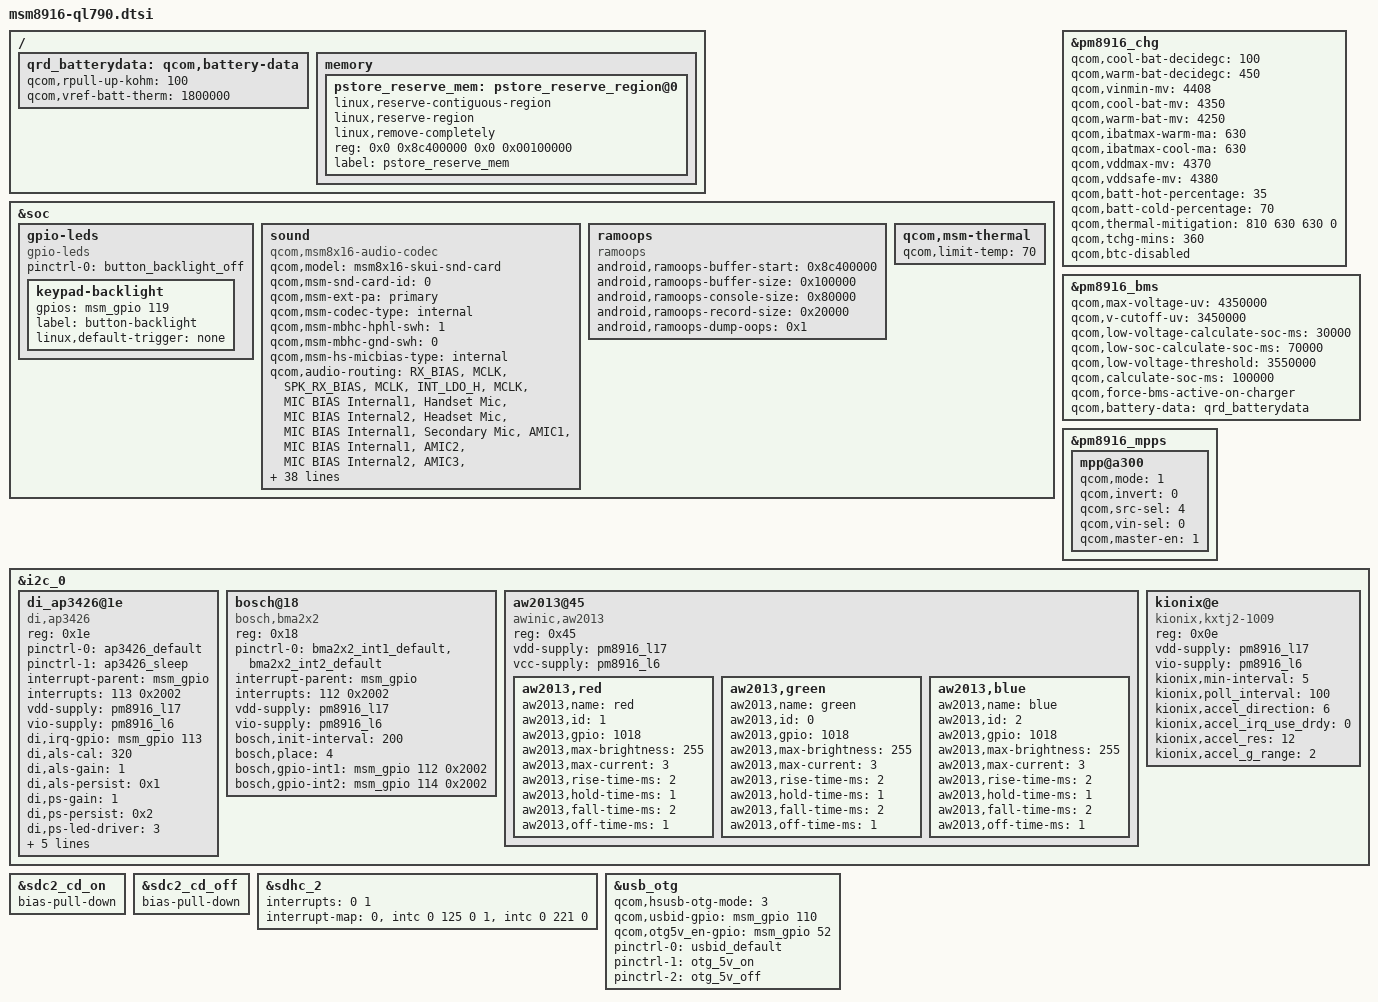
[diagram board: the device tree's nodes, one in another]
/* Copyright (c) 2014, The Linux Foundation. All rights reserved.
 *
 * This program is free software; you can redistribute it and/or modify
 * it under the terms of the GNU General Public License version 2 and
 * only version 2 as published by the Free Software Foundation.
 *
 * This program is distributed in the hope that it will be useful,
 * but WITHOUT ANY WARRANTY; without even the implied warranty of
 * MERCHANTABILITY or FITNESS FOR A PARTICULAR PURPOSE.  See the
 * GNU General Public License for more details.
 */

#include "msm8916-ql790-misc.dtsi"
#include "msm8916-ql790-camera.dtsi"
#include "msm8916-ql790-lcd_panel-settings.dtsi"
#include "msm8916-ql790-pm8916.dtsi"
#include "msm8916-ql790-tp.dtsi"

&soc {
	gpio-leds {
		compatible = "gpio-leds";
		status = "okay";
		pinctrl-names = "default";
		pinctrl-0 = <&button_backlight_off>;

		keypad-backlight {
			gpios = <&msm_gpio 119 0>;
			label = "button-backlight";
			linux,default-trigger = "none";
		};
	};

	sound {
		compatible = "qcom,msm8x16-audio-codec";
		qcom,model = "msm8x16-skui-snd-card";
		qcom,msm-snd-card-id = <0>;
		qcom,msm-ext-pa = "primary";
		qcom,msm-codec-type = "internal";
		qcom,msm-mbhc-hphl-swh = <1>;
		qcom,msm-mbhc-gnd-swh = <0>;
		qcom,msm-hs-micbias-type = "internal";
		qcom,audio-routing =
			"RX_BIAS", "MCLK",
			"SPK_RX_BIAS", "MCLK",
			"INT_LDO_H", "MCLK",
			"MIC BIAS Internal1", "Handset Mic",
			"MIC BIAS Internal2", "Headset Mic",
			"MIC BIAS Internal1", "Secondary Mic",
			"AMIC1", "MIC BIAS Internal1",
			"AMIC2", "MIC BIAS Internal2",
			"AMIC3", "MIC BIAS Internal1";
		pinctrl-names = "cdc_lines_act",
				"cdc_lines_sus";
		pinctrl-0 = <&cdc_pdm_lines_act>;
		pinctrl-1 = <&cdc_pdm_lines_sus>;
		qcom,ext-spk-amp-gpio = <&msm_gpio 112 0>;
		asoc-platform = <&pcm0>, <&pcm1>, <&voip>, <&voice>,
				<&loopback>, <&compress>, <&hostless>,
				<&afe>, <&lsm>, <&routing>, <&lpa>;
		asoc-platform-names = "msm-pcm-dsp.0", "msm-pcm-dsp.1",
				"msm-voip-dsp", "msm-pcm-voice", "msm-pcm-loopback",
				"msm-compress-dsp", "msm-pcm-hostless", "msm-pcm-afe",
				"msm-lsm-client", "msm-pcm-routing", "msm-pcm-lpa";
		asoc-cpu = <&dai_pri_auxpcm>, <&dai_hdmi>,
				<&dai_mi2s0>, <&dai_mi2s1>, <&dai_mi2s2>, <&dai_mi2s3>,
				<&sb_0_rx>, <&sb_0_tx>, <&sb_1_rx>, <&sb_1_tx>,
				<&sb_3_rx>, <&sb_3_tx>, <&sb_4_rx>, <&sb_4_tx>,
				<&bt_sco_rx>, <&bt_sco_tx>, <&bt_a2dp_rx>,
				<&int_fm_rx>, <&int_fm_tx>,
				<&afe_pcm_rx>, <&afe_pcm_tx>, <&afe_proxy_rx>, <&afe_proxy_tx>,
				<&incall_record_rx>, <&incall_record_tx>, <&incall_music_rx>,
				<&incall_music_2_rx>;
		asoc-cpu-names = "msm-dai-q6-auxpcm.1", "msm-dai-q6-hdmi.8",
				"msm-dai-q6-mi2s.0", "msm-dai-q6-mi2s.1",
				"msm-dai-q6-mi2s.2", "msm-dai-q6-mi2s.3",
				"msm-dai-q6-dev.16384", "msm-dai-q6-dev.16385",
				"msm-dai-q6-dev.16386", "msm-dai-q6-dev.16387",
				"msm-dai-q6-dev.16390", "msm-dai-q6-dev.16391",
				"msm-dai-q6-dev.16392", "msm-dai-q6-dev.16393",
				"msm-dai-q6-dev.12288", "msm-dai-q6-dev.12289",
				"msm-dai-q6-dev.12290", "msm-dai-q6-dev.12292",
				"msm-dai-q6-dev.12293",	"msm-dai-q6-dev.224",
				"msm-dai-q6-dev.225", "msm-dai-q6-dev.241",
				"msm-dai-q6-dev.240", "msm-dai-q6-dev.32771",
				"msm-dai-q6-dev.32772", "msm-dai-q6-dev.32773",
				"msm-dai-q6-dev.32770";
		asoc-codec = <&stub_codec>, <&pm8916_tombak_dig>;
		asoc-codec-names = "msm-stub-codec.1", "tombak_codec";
	};

	ramoops {
		compatible = "ramoops";
		status = "ok";

		android,ramoops-buffer-start = <0x8c400000>;
		android,ramoops-buffer-size = <0x100000>;
		android,ramoops-console-size = <0x80000>;
		android,ramoops-record-size = <0x20000>;
		android,ramoops-dump-oops = <0x1>;
	};

	qcom,msm-thermal {
		qcom,limit-temp = <70>;
	};
};

&pm8916_chg {
	qcom,cool-bat-decidegc = <100>;
	qcom,warm-bat-decidegc = <450>;
	qcom,vinmin-mv = <4408>;
	qcom,cool-bat-mv = <4350>;
	qcom,warm-bat-mv = <4250>;
	qcom,ibatmax-warm-ma = <630>;
	qcom,ibatmax-cool-ma = <630>;
	qcom,vddmax-mv = <4370>;
	qcom,vddsafe-mv = <4380>;
	qcom,batt-hot-percentage = <35>;
	qcom,batt-cold-percentage = <70>;
	qcom,thermal-mitigation = <810 630 630 0>;
	qcom,tchg-mins = <360>;
	status = "okay";
};
&pm8916_bms {
	qcom,max-voltage-uv = <4350000>;
	qcom,v-cutoff-uv = <3450000>;
	qcom,low-voltage-calculate-soc-ms = <30000>;
	qcom,low-soc-calculate-soc-ms = <70000>;
	qcom,low-voltage-threshold = <3550000>;
	qcom,calculate-soc-ms = <100000>;
};

&pm8916_chg {
	status = "ok";
	qcom,btc-disabled;
};

/ {
	qrd_batterydata: qcom,battery-data {
	qcom,rpull-up-kohm = <100>;
	qcom,vref-batt-therm = <1800000>;

		#include "msm8916-ql790-sunwoda-4v35-2000mah.dtsi"
	};
};

&pm8916_bms {
	status = "okay";
	qcom,force-bms-active-on-charger;
	qcom,battery-data = <&qrd_batterydata>;
};

&pm8916_mpps {
	mpp@a300 { /* MPP 4 */
		/* Backlight PWM */
		qcom,mode = <1>;		/* Digital output */
		qcom,invert = <0>;		/* Disable invert */
		qcom,src-sel = <4>;		/* DTEST1 */
		qcom,vin-sel = <0>;		/* VPH_PWR */
		qcom,master-en = <1>;		/* Enable MPP */
	};
};

&i2c_0 { /* BLSP1 QUP2 */
	di_ap3426@1e {
		compatible = "di,ap3426";
		reg = <0x1e>;
		pinctrl-names = "default","sleep";
		pinctrl-0 = <&ap3426_default>;
		pinctrl-1 = <&ap3426_sleep>;
		interrupt-parent = <&msm_gpio>;
		interrupts = <113 0x2002>;
		vdd-supply = <&pm8916_l17>;
		vio-supply = <&pm8916_l6>;
		di,irq-gpio = <&msm_gpio 113 0x2002>;
		di,als-cal = <320>;
		di,als-gain = <1>;
		di,als-persist = <0x1>;
		di,ps-gain = <1>;
		di,ps-persist = <0x2>;
		di,ps-led-driver = <3>;
		di,ps-mean-time = <0x2>;
		di,ps-integrated-time = <0xc>;
		di,wakeup-threshold = <4>;
		di,als-sensitivity = <3000 400 100 1>;
		di,ps-distance-table = <950 500 250 160 105 75>;
	};

	bosch@18 { /* Accelerometer sensor */
		compatible = "bosch,bma2x2";
		reg = <0x18>;
		pinctrl-names = "default";
		pinctrl-0 = <&bma2x2_int1_default &bma2x2_int2_default>;
		interrupt-parent = <&msm_gpio>;
		interrupts = <112 0x2002>;
		vdd-supply = <&pm8916_l17>;
		vio-supply = <&pm8916_l6>;
		bosch,init-interval = <200>;
		bosch,place = <4>;
		bosch,gpio-int1 = <&msm_gpio 112 0x2002>;
		bosch,gpio-int2 = <&msm_gpio 114 0x2002>;
	};

	aw2013@45 {
		compatible = "awinic,aw2013";
		reg = <0x45>;
		vdd-supply = <&pm8916_l17>;
		vcc-supply = <&pm8916_l6>;

		aw2013,red {
			aw2013,name = "red";
			aw2013,id = <1>;
			aw2013,gpio = <1018>;
			aw2013,max-brightness = <255>;
			aw2013,max-current = <3>;
			aw2013,rise-time-ms = <2>;
			aw2013,hold-time-ms = <1>;
			aw2013,fall-time-ms = <2>;
			aw2013,off-time-ms = <1>;
		};

		aw2013,green {
			aw2013,name = "green";
			aw2013,id = <0>;
			aw2013,gpio = <1018>;
			aw2013,max-brightness = <255>;
			aw2013,max-current = <3>;
			aw2013,rise-time-ms = <2>;
			aw2013,hold-time-ms = <1>;
			aw2013,fall-time-ms = <2>;
			aw2013,off-time-ms = <1>;
		};

		aw2013,blue {
			aw2013,name = "blue";
			aw2013,id = <2>;
			aw2013,gpio = <1018>;
			aw2013,max-brightness = <255>;
			aw2013,max-current = <3>;
			aw2013,rise-time-ms = <2>;
			aw2013,hold-time-ms = <1>;
			aw2013,fall-time-ms = <2>;
			aw2013,off-time-ms = <1>;
		};
	};

	kionix@e {
		compatible = "kionix,kxtj2-1009";
		reg = <0x0e>;
		vdd-supply = <&pm8916_l17>;
		vio-supply = <&pm8916_l6>;
		kionix,min-interval = <5>;
		kionix,poll_interval = <100>;
		kionix,accel_direction = <6>;
		kionix,accel_irq_use_drdy = <0>;
		kionix,accel_res = <12>;
		kionix,accel_g_range = <2>;
	};
};

&sdc2_cd_on {
	/delete-property/ bias-pull-up;
	bias-pull-down;
};

&sdc2_cd_off {
	/delete-property/ bias-disable;
	bias-pull-down;
};

&sdhc_2 {
	interrupts = <0 1>;
	interrupt-map = <0 &intc 0 125 0
		1 &intc 0 221 0>;
	interrupt-names = "hc_irq", "pwr_irq";
	/delete-property/ cd-gpios;
};

/ {
	memory {
		pstore_reserve_mem: pstore_reserve_region@0 {
			linux,reserve-contiguous-region;
			linux,reserve-region;
			linux,remove-completely;
			reg = <0x0 0x8c400000 0x0 0x00100000>;
			label = "pstore_reserve_mem";
		};
	};
};

&usb_otg {
	qcom,hsusb-otg-mode = <3>;
	qcom,usbid-gpio = <&msm_gpio 110 0>;
	qcom,otg5v_en-gpio = <&msm_gpio 52 0>;
	pinctrl-names = "default", "active", "sleep";
	pinctrl-0 = <&usbid_default>;
	pinctrl-1 = <&otg_5v_on>;
	pinctrl-2 = <&otg_5v_off>;
};
